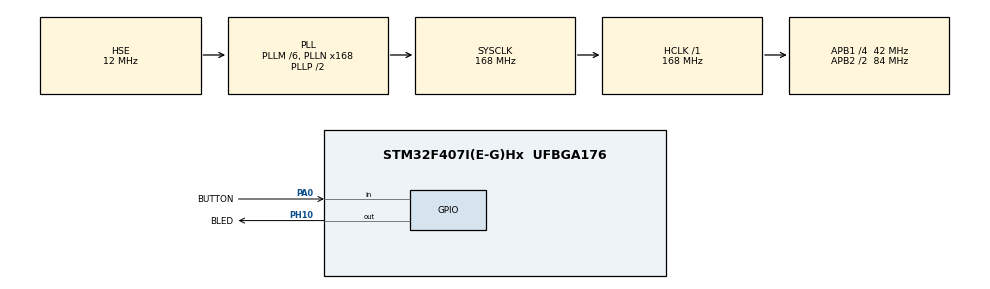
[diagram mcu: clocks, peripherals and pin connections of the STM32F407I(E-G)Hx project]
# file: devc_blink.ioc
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Mcu.Family=STM32F4
Mcu.Name=STM32F407I(E-G)Hx
Mcu.Package=UFBGA176
NVIC.PriorityGroup=NVIC_PRIORITYGROUP_4
PA0-WKUP.GPIO_Label=BUTTON
PA0-WKUP.GPIO_PuPd=GPIO_PULLDOWN
PA0-WKUP.Signal=GPIO_Input
PA13.Mode=Serial_Wire
PA13.Signal=SYS_JTMS-SWDIO
PA14.Mode=Serial_Wire
PA14.Signal=SYS_JTCK-SWCLK
PH0-OSC_IN.Mode=HSE-External-Oscillator
PH0-OSC_IN.Signal=RCC_OSC_IN
PH1-OSC_OUT.Mode=HSE-External-Oscillator
PH1-OSC_OUT.Signal=RCC_OSC_OUT
PH10.GPIO_Label=BLED
PH10.PinState=GPIO_PIN_RESET
PH10.Signal=GPIO_Output
ProjectManager.HeapSize=0x200
ProjectManager.StackSize=0x400
ProjectManager.TargetToolchain=STM32CubeIDE
RCC.48MHZClocksFreq_Value=84000000
RCC.AHBFreq_Value=168000000
RCC.APB1CLKDivider=RCC_HCLK_DIV4
RCC.APB1Freq_Value=42000000
RCC.APB1TimFreq_Value=84000000
RCC.APB2CLKDivider=RCC_HCLK_DIV2
RCC.APB2Freq_Value=84000000
RCC.APB2TimFreq_Value=168000000
RCC.CortexFreq_Value=168000000
RCC.HCLKFreq_Value=168000000
RCC.HSE_VALUE=12000000
RCC.HSI_VALUE=16000000
RCC.LSE_VALUE=32768
RCC.PLLM=6
RCC.PLLN=168
RCC.PLLSourceVirtual=RCC_PLLSOURCE_HSE
RCC.SYSCLKFreq_VALUE=168000000
RCC.SYSCLKSource=RCC_SYSCLKSOURCE_PLLCLK
RCC.VCOOutputFreq_Value=336000000
board=custom

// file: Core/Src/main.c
/* USER CODE BEGIN Header */
/**
  ******************************************************************************
  * @file           : main.c
  * @brief          : Main program body
  ******************************************************************************
  * @attention
  *
  * <h2><center>&copy; Copyright (c) 2021 STMicroelectronics.
  * All rights reserved.</center></h2>
  *
  * This software component is licensed by ST under BSD 3-Clause license,
  * the "License"; You may not use this file except in compliance with the
  * License. You may obtain a copy of the License at:
  *                        opensource.org/licenses/BSD-3-Clause
  *
  ******************************************************************************
  */
/* USER CODE END Header */
#include "main.h"
#include "gpio.h"

void SystemClock_Config(void);

/* USER CODE BEGIN 0 */

void HAL_GPIO_EXTI_Callback(uint16_t GPIO_Pin)
{
	//insert interrupt code here! (set it up first though)
	/* to setup
	 *-> open the .ioc file
	 *-> change the pin to external interrupt mode
	 *-> enable the EXTI call back under NVIC
	 *-> insert code here!
	 *-> */
}
/* USER CODE END 0 */

int main(void)
{

  /* MCU Configuration--------------------------------------------------------*/

  /* Reset of all peripherals, Initializes the Flash interface and the Systick. */
  HAL_Init();

  /* Configure the system clock */
  SystemClock_Config();

  /* Initialize all configured peripherals */
  MX_GPIO_Init();
  /* USER CODE BEGIN 2 */
  uint8_t blinking = 1;

  /* USER CODE END 2 */

  /* Infinite loop */
  /* USER CODE BEGIN WHILE */
  while (1)
  {
	  /* Checks if the button is pressed*/
	  if (HAL_GPIO_ReadPin(BUTTON_GPIO_Port, BUTTON_Pin) == GPIO_PIN_RESET)
	  {
		  //toggles the blinking mode
		blinking = 1 - blinking;
	  }

	  //checks if it's in blinking mode
	  if (blinking == 1)
	  {  /*Turns on the blue LED*/
		HAL_GPIO_TogglePin(BLED_GPIO_Port, BLED_Pin);
	  }
		HAL_Delay(1000);	//because the MCU isn't checking for the button when it's in this delay, it won't change the mode if the button is pressed
							//add in the interrupt to change it outside of the delay!
    /* USER CODE END WHILE */

  }
}

void SystemClock_Config(void)
{
  RCC_OscInitTypeDef RCC_OscInitStruct = {0};
  RCC_ClkInitTypeDef RCC_ClkInitStruct = {0};

  /** Configure the main internal regulator output voltage
  */
  __HAL_RCC_PWR_CLK_ENABLE();
  __HAL_PWR_VOLTAGESCALING_CONFIG(PWR_REGULATOR_VOLTAGE_SCALE1);
  /** Initializes the RCC Oscillators according to the specified parameters
  * in the RCC_OscInitTypeDef structure.
  */
  RCC_OscInitStruct.OscillatorType = RCC_OSCILLATORTYPE_HSE;
  RCC_OscInitStruct.HSEState = RCC_HSE_ON;
  RCC_OscInitStruct.PLL.PLLState = RCC_PLL_ON;
  RCC_OscInitStruct.PLL.PLLSource = RCC_PLLSOURCE_HSE;
  RCC_OscInitStruct.PLL.PLLM = 6;
  RCC_OscInitStruct.PLL.PLLN = 168;
  RCC_OscInitStruct.PLL.PLLP = RCC_PLLP_DIV2;
  RCC_OscInitStruct.PLL.PLLQ = 4;
  if (HAL_RCC_OscConfig(&RCC_OscInitStruct) != HAL_OK)
  {
    Error_Handler();
  }
  /** Initializes the CPU, AHB and APB buses clocks
  */
  RCC_ClkInitStruct.ClockType = RCC_CLOCKTYPE_HCLK|RCC_CLOCKTYPE_SYSCLK
                              |RCC_CLOCKTYPE_PCLK1|RCC_CLOCKTYPE_PCLK2;
  RCC_ClkInitStruct.SYSCLKSource = RCC_SYSCLKSOURCE_PLLCLK;
  RCC_ClkInitStruct.AHBCLKDivider = RCC_SYSCLK_DIV1;
  RCC_ClkInitStruct.APB1CLKDivider = RCC_HCLK_DIV4;
  RCC_ClkInitStruct.APB2CLKDivider = RCC_HCLK_DIV2;

  if (HAL_RCC_ClockConfig(&RCC_ClkInitStruct, FLASH_LATENCY_5) != HAL_OK)
  {
    Error_Handler();
  }
}

void Error_Handler(void)
{
  __disable_irq();
  while (1)
  {
  }
}

/************************ (C) COPYRIGHT STMicroelectronics *****END OF FILE****/
